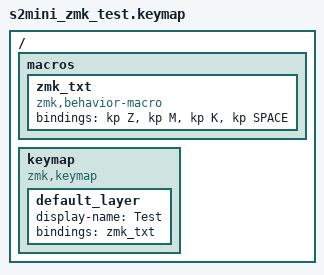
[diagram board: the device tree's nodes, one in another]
/*
 * Wciśnięcie "0" wpisuje "zmk " (makro ZMK).
 * SPDX-License-Identifier: MIT
 */
#include <behaviors.dtsi>
#include <dt-bindings/zmk/keys.h>

/ {
    macros {
        zmk_txt: zmk_txt {
            compatible = "zmk,behavior-macro";
            #binding-cells = <0>;
            bindings = <&kp Z &kp M &kp K &kp SPACE>;
        };
    };

    keymap {
        compatible = "zmk,keymap";

        default_layer {
            display-name = "Test";
            bindings = <&zmk_txt>;
        };
    };
};
